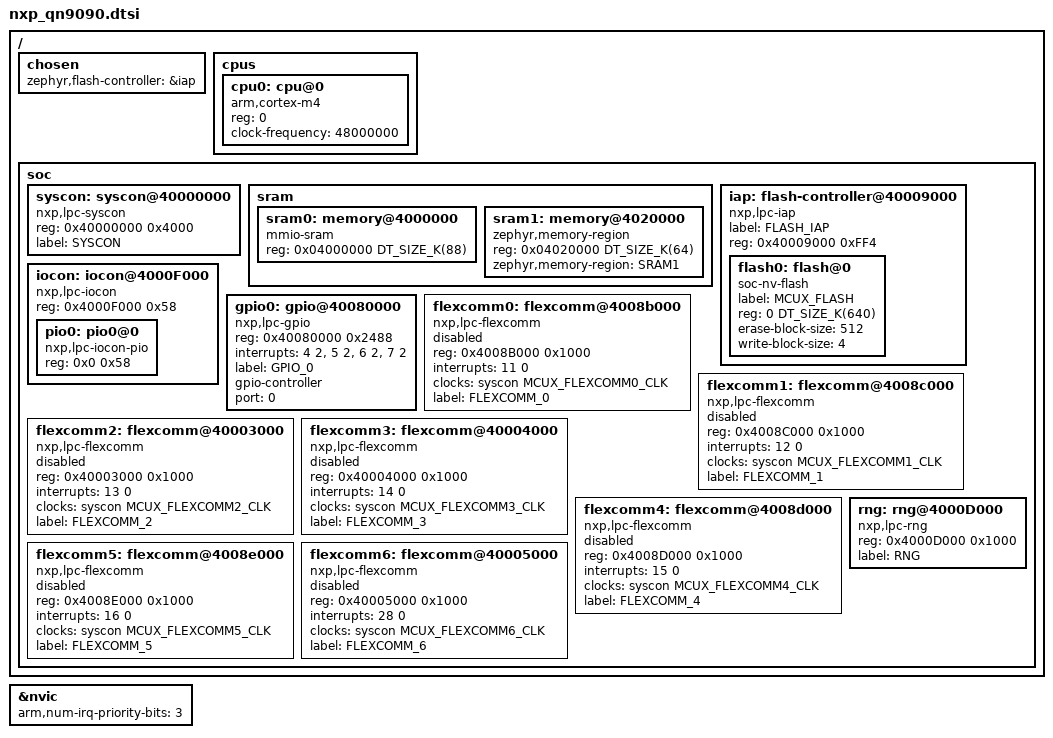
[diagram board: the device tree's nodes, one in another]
/*
 * Copyright 2021 Vincent van der Locht
 * Copyright 2022 Hessel van der Molen, sendrato.com
 *
 * SPDX-License-Identifier: Apache-2.0
 */

#include <mem.h>
#include <arm/armv7-m.dtsi>
#include <dt-bindings/clock/mcux_lpc_syscon_clock.h>
#include <dt-bindings/gpio/gpio.h>
#include <dt-bindings/i2c/i2c.h>

/ {
	chosen {
		zephyr,flash-controller = &iap;
	};

	cpus {
		#address-cells = <1>;
		#size-cells = <0>;

		cpu0: cpu@0 {
			device_type = "cpu";
			compatible = "arm,cortex-m4";
			reg = <0>;
            clock-frequency = <48000000>;
		};
	};

	soc {

		syscon: syscon@40000000 {
			compatible = "nxp,lpc-syscon";
			reg = <0x40000000 0x4000>;
			label = "SYSCON";
			#clock-cells = <1>;
		};

        sram {
            #address-cells = <1>;
            #size-cells = <1>;

            sram0: memory@4000000 {
                compatible = "mmio-sram";
                reg = <0x04000000 DT_SIZE_K(88)>;
            };

            sram1: memory@4020000 {
                compatible = "zephyr,memory-region", "mmio-sram";
                reg = <0x04020000 DT_SIZE_K(64)>;
                zephyr,memory-region = "SRAM1";
            };
        };

		iap: flash-controller@40009000 {
			compatible = "nxp,lpc-iap";
			label = "FLASH_IAP";
			reg = <0x40009000 0xFF4>;
			#address-cells = <1>;
			#size-cells = <1>;
			flash0: flash@0 {
				compatible = "soc-nv-flash";
				label = "MCUX_FLASH";
				reg = <0 DT_SIZE_K(640)>;
				erase-block-size = <512>;
				write-block-size = <4>;
			};
		};

        iocon: iocon@4000F000 {
            compatible = "nxp,lpc-iocon";
            reg = <0x4000F000 0x58>;
            #address-cells = <1>;
            #size-cells = <1>;
            ranges = <0x0 0x4000F000 0x58>;
            pio0: pio0@0 {
                compatible = "nxp,lpc-iocon-pio";
                reg = <0x0 0x58>;
            };
        };

        // GPIO, irq 4,5,6,7
		gpio0: gpio@40080000 {
			compatible = "nxp,lpc-gpio";
			reg = <0x40080000 0x2488>;
			interrupts = <4 2>,<5 2>,<6 2>,<7 2>;
			label = "GPIO_0";
			gpio-controller;
			#gpio-cells = <2>;
            port = <0>;
		};

        // Flexcomm Interface 0 (USART0, FLEXCOMM0)
		flexcomm0: flexcomm@4008b000 {
			compatible = "nxp,lpc-flexcomm";
			reg = <0x4008B000 0x1000>;
			interrupts = <11 0>;
			clocks = <&syscon MCUX_FLEXCOMM0_CLK>;
			label = "FLEXCOMM_0";
			status = "disabled";
		};

        // Flexcomm Interface 1 (USART1, FLEXCOMM1)
		flexcomm1: flexcomm@4008c000 {
			compatible = "nxp,lpc-flexcomm";
			reg = <0x4008C000 0x1000>;
			interrupts = <12 0>;
			clocks = <&syscon MCUX_FLEXCOMM1_CLK>;
			label = "FLEXCOMM_1";
			status = "disabled";
		};

        // Flexcomm Interface 2 (I2C0, FLEXCOMM2)
		flexcomm2: flexcomm@40003000 {
			compatible = "nxp,lpc-flexcomm";
			reg = <0x40003000 0x1000>;
			interrupts = <13 0>;
			clocks = <&syscon MCUX_FLEXCOMM2_CLK>;
			label = "FLEXCOMM_2";
			status = "disabled";
		};

        // Flexcomm Interface 3 (I2C1, FLEXCOMM3)
		flexcomm3: flexcomm@40004000 {
			compatible = "nxp,lpc-flexcomm";
			reg = <0x40004000 0x1000>;
			interrupts = <14 0>;
			clocks = <&syscon MCUX_FLEXCOMM3_CLK>;
			label = "FLEXCOMM_3";
			status = "disabled";
		};

        // Flexcomm Interface 4 (SPI0, FLEXCOMM4)
		flexcomm4: flexcomm@4008d000 {
			compatible = "nxp,lpc-flexcomm";
			reg = <0x4008D000 0x1000>;
			interrupts = <15 0>;
			clocks = <&syscon MCUX_FLEXCOMM4_CLK>;
			label = "FLEXCOMM_4";
			status = "disabled";
		};

        // Flexcomm Interface 5 (SPI1, FLEXCOMM)
		flexcomm5: flexcomm@4008e000 {
			compatible = "nxp,lpc-flexcomm";
			reg = <0x4008E000 0x1000>;
			interrupts = <16 0>;
			clocks = <&syscon MCUX_FLEXCOMM5_CLK>;
			label = "FLEXCOMM_5";
			status = "disabled";
		};

        // Flexcomm Interface6 (I2C2, FLEXCOMM6)
		flexcomm6: flexcomm@40005000 {
			compatible = "nxp,lpc-flexcomm";
			reg = <0x40005000 0x1000>;
			interrupts = <28 0>;
			clocks = <&syscon MCUX_FLEXCOMM6_CLK>;
			label = "FLEXCOMM_6";
			status = "disabled";
		};

        rng: rng@4000D000 {
            compatible = "nxp,lpc-rng";
            reg = <0x4000D000 0x1000>;
            status = "okay";
            label = "RNG";
        };
	};
};

&nvic {
	arm,num-irq-priority-bits = <3>;
};
